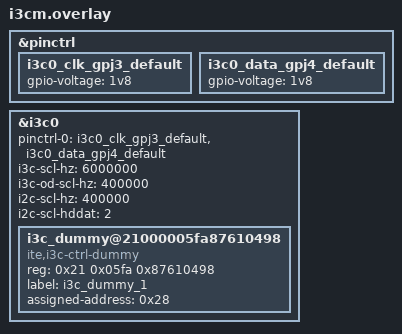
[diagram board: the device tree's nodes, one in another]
/*
 * Copyright (c) 2025 ITE Corporation. All Rights Reserved.
 *
 * SPDX-License-Identifier: Apache-2.0
 */

&pinctrl {
	i3c0_clk_gpj3_default: i3c0_clk_gpj3_default {
		gpio-voltage = "1v8";
	};
	i3c0_data_gpj4_default: i3c0_data_gpj4_default {
		gpio-voltage = "1v8";
	};
};

&i3c0 {
	status = "okay";
	pinctrl-0 = <&i3c0_clk_gpj3_default
		     &i3c0_data_gpj4_default>;
	pinctrl-names = "default";
	i3c-scl-hz = <6000000>;
	i3c-od-scl-hz = <400000>;
	i2c-scl-hz = <400000>;
	i2c-scl-hddat = <2>;

	i3c_dummy@21000005fa87610498 {
		compatible = "ite,i3c-ctrl-dummy";
		reg = <0x21 0x05fa 0x87610498>;
		label = "i3c_dummy_1";
		assigned-address = <0x28>;
		status = "okay";
	};
};
